# PMM_45 register map
Vendor: Texas Instruments
Peripheral module from a debugger description file (folder msp430).
Registers are 16-bit, read-write, no defined reset value unless marked. A register's access mark holds for its fields unless they carry their own. Offsets are as the file gives them; lines under a group give offsets from that group; [hi:lo] are bit positions; {n}, {i} and the like mark numbered series; 'fields as' and 'values as' point back to an identical list; <NAME> marks a mode.

## PMM
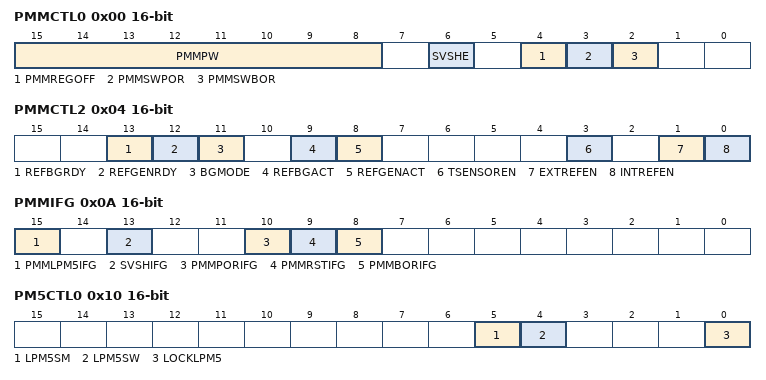
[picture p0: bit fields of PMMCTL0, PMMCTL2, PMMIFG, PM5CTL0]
0x00 PMMCTL0 — PMM control register 0
  [15:8] PMMPW — PMM password.
  [6] SVSHE — High-side SVS enable.
    0=High-side SVS (SVSH) is disabled in LPM2, LPM3, LPM4, LPM3.5, and LPM4.5. SVSH is always enabled in active mode, LPM0, and LPM1.; 1=SVSH is always enabled
  [4] PMMREGOFF — Regulator off
    0=Regulator remains on when going into LPM3 or LPM4; 1=Regulator is turned off when going to LPM3 or LPM4. System enters LPM3.5 or LPM4.5, respectively.
  [3] PMMSWPOR — Software POR.
    0=Normal operation; 1=Set to 1 to trigger a POR
  [2] PMMSWBOR — Software brownout reset.
    0=Normal operation; 1=Set to 1 to trigger a BOR
0x04 PMMCTL2 access per field — Power Management Module Control Register 2
  [13] REFBGRDY rw — Buffered bandgap voltage ready status.
    0=Buffered bandgap voltage is not ready to be used; 1=Buffered bandgap voltage is ready to be used
  [12] REFGENRDY rw — Variable reference voltage ready status.
    0=Reference voltage output is not ready to be used; 1=Reference voltage output is ready to be used
  [11] BGMODE rw — Bandgap mode. Ready only.
    0=Static mode (higher precision); 1=Sampled mode (lower power consumption)
  [9] REFBGACT ro — Reference bandgap active. Ready only.
    0=Reference bandgap buffer not active; 1=Reference bandgap buffer active
  [8] REFGENACT ro — Reference generator active. Read only.
    0=Reference generator not active; 1=Reference generator active
  [3] TSENSOREN rw — Temperature sensor enable
    0=Disable temperature sensor; 1=Enable temperature sensor
  [1] EXTREFEN rw — External reference output enable
    0=Disable external reference output; 1=Enable internal reference output
  [0] INTREFEN rw — Internal reference enable
    0=Disable internal reference; 1=Enable internal reference
0x0A PMMIFG — PMM interrupt flag register
  [15] PMMLPM5IFG — LPMx.5 flag.
    0=Reset not due to wake-up from LPMx.5; 1=Reset due to wake-up from LPMx.5
  [13] SVSHIFG — High-side SVS interrupt flag.
    0=Reset not due to SVSH; 1=Reset due to SVSH
  [10] PMMPORIFG — PMM software POR interrupt flag.
    0=Reset not due to PMMSWPOR; 1=Reset due to PMMSWPOR
  [9] PMMRSTIFG — PMM reset pin interrupt flag.
    0=Reset not due to reset pin; 1=Reset due to reset pin
  [8] PMMBORIFG — PMM software brownout reset interrupt flag.
    0=Reset not due to PMMSWBOR; 1=Reset due to PMMSWBOR
0x10 PM5CTL0 — Power mode 5 control register 0
  [5] LPM5SM — Specifies the operation mode of the LPM3.5 switch.
    0=Automatic mode for LPM3.5 switch that the switch is fully handled by the circuitry during mode switch; 1=Manual mode for LPM3.5 switch that the switch is specified by LPM5SW bit setting in software
  [4] LPM5SW — Reports or sets the LPM3.5 switch connection upon the switch mode set by LPM5SM. When this bit is set, the VLPM3.5 domain can accept full-speed read and write operation by CPU MCLK. If the switch is disconnected, all peripherals within this domain can only accept the operation no more than 40 kHz. In automatic mode (LPM5SM = 0), this bit represents the switch connection between Vcore and VLPM3.5. Any write to this bit has no effect. In manual mode (LPM5SM = 1), this bit can be fully read and written by software. When this bit is set, the switch connection between Vcore and VLPM3.5 is connected. Otherwise, the switch is disconnected.
    0=LPMx.5 switch disconnected; 1=LPMx.5 switch connected
  [0] LOCKLPM5 — LPMx.5 Lock Bit
    0=LPMx.5 configuration is not locked and defaults to its reset condition; 1=LPMx.5 configuration remains locked. Pin state is held during LPMx.5 entry and exit.
